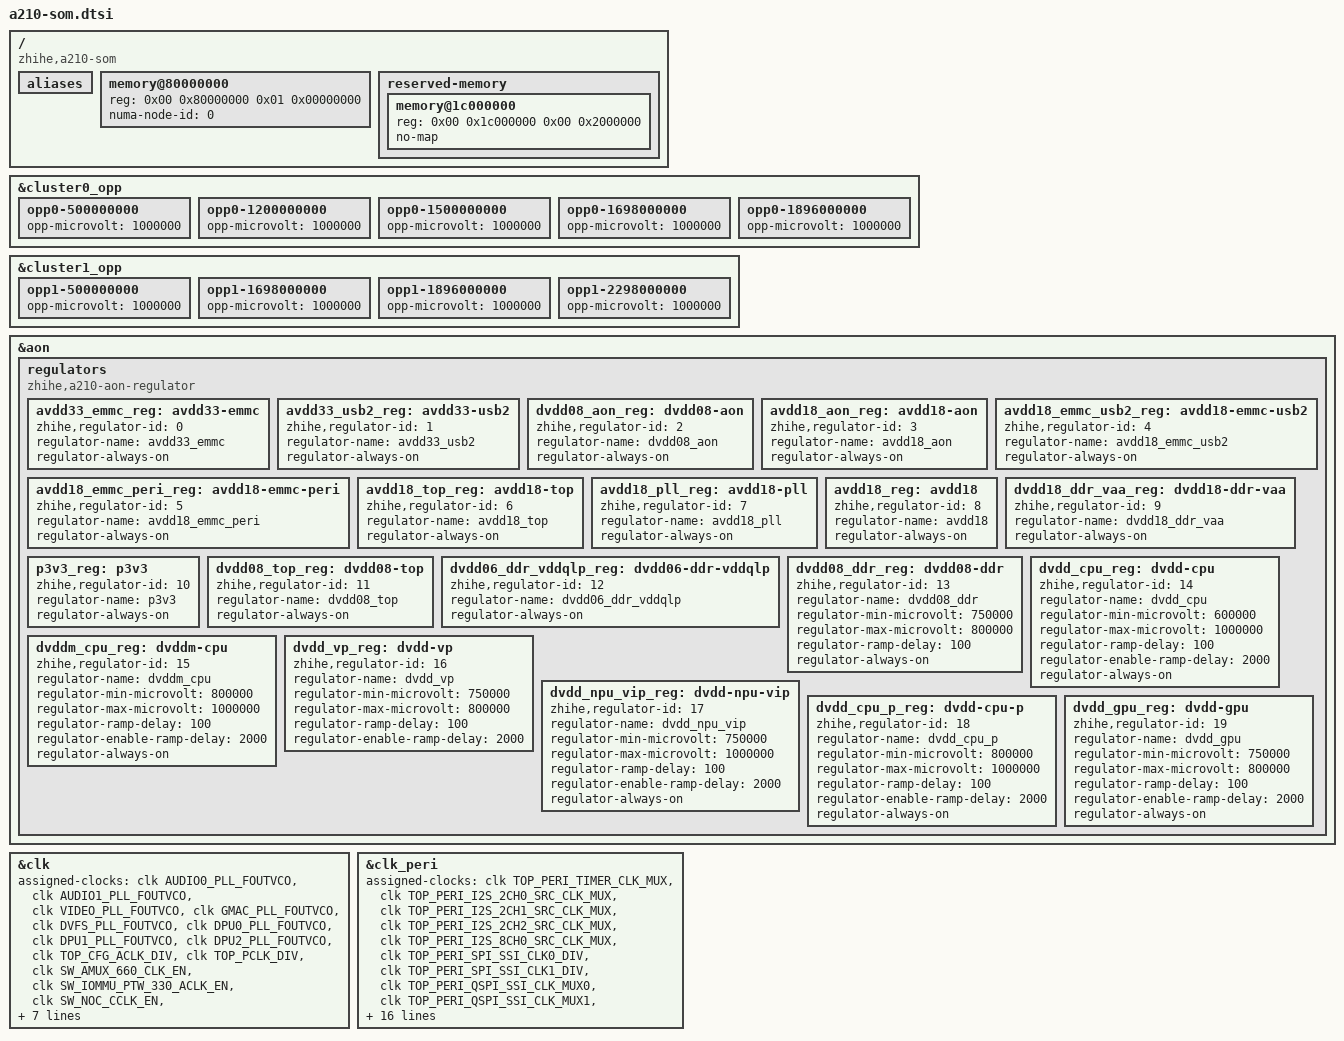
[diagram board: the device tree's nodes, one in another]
// SPDX-License-Identifier: (GPL-2.0-only OR BSD-2-Clause)
/* Shared hardware and operating policy of the A210 SODIMM module. */
#include "a210.dtsi"

/ {
	compatible = "zhihe,a210-som", "zhihe,a210";

	aliases {
	};

	/* Boot firmware replaces this placeholder after DDR training. */
	memory@80000000 {
		device_type = "memory";
		reg = <0x00 0x80000000  0x01 0x00000000>; /* 4G */
		numa-node-id = <0>;
	};

	reserved-memory {
		#address-cells = <2>;
		#size-cells = <2>;
		ranges;

		memory@1c000000 {
			reg = <0x00 0x1c000000 0x00 0x2000000>;
			no-map;
		};
	};
};

&cluster0_opp {
	opp0-500000000 {
		opp-microvolt = <1000000>;
	};
	opp0-1200000000 {
		opp-microvolt = <1000000>;
	};
	opp0-1500000000 {
		opp-microvolt = <1000000>;
	};
	opp0-1698000000 {
		opp-microvolt = <1000000>;
	};
	opp0-1896000000 {
		opp-microvolt = <1000000>;
	};
};

&cluster1_opp {
	opp1-500000000 {
		opp-microvolt = <1000000>;
	};
	opp1-1698000000 {
		opp-microvolt = <1000000>;
	};
	opp1-1896000000 {
		opp-microvolt = <1000000>;
	};
	opp1-2298000000 {
		opp-microvolt = <1000000>;
	};
};

&aon {
	regulators {
		compatible = "zhihe,a210-aon-regulator";

		avdd33_emmc_reg: avdd33-emmc {
			zhihe,regulator-id = <0>;
			regulator-name = "avdd33_emmc";
			regulator-always-on;
		};

		avdd33_usb2_reg: avdd33-usb2 {
			zhihe,regulator-id = <1>;
			regulator-name = "avdd33_usb2";
			regulator-always-on;
		};

		dvdd08_aon_reg: dvdd08-aon {
			zhihe,regulator-id = <2>;
			regulator-name = "dvdd08_aon";
			regulator-always-on;
		};

		avdd18_aon_reg: avdd18-aon {
			zhihe,regulator-id = <3>;
			regulator-name = "avdd18_aon";
			regulator-always-on;
		};

		avdd18_emmc_usb2_reg: avdd18-emmc-usb2 {
			zhihe,regulator-id = <4>;
			regulator-name = "avdd18_emmc_usb2";
			regulator-always-on;
		};

		avdd18_emmc_peri_reg: avdd18-emmc-peri {
			zhihe,regulator-id = <5>;
			regulator-name = "avdd18_emmc_peri";
			regulator-always-on;
		};

		avdd18_top_reg: avdd18-top {
			zhihe,regulator-id = <6>;
			regulator-name = "avdd18_top";
			regulator-always-on;
		};

		avdd18_pll_reg: avdd18-pll {
			zhihe,regulator-id = <7>;
			regulator-name = "avdd18_pll";
			regulator-always-on;
		};

		avdd18_reg: avdd18 {
			zhihe,regulator-id = <8>;
			regulator-name = "avdd18";
			regulator-always-on;
		};

		dvdd18_ddr_vaa_reg: dvdd18-ddr-vaa {
			zhihe,regulator-id = <9>;
			regulator-name = "dvdd18_ddr_vaa";
			regulator-always-on;
		};

		p3v3_reg: p3v3 {
			zhihe,regulator-id = <10>;
			regulator-name = "p3v3";
			regulator-always-on;
		};

		dvdd08_top_reg: dvdd08-top {
			zhihe,regulator-id = <11>;
			regulator-name = "dvdd08_top";
			regulator-always-on;
		};

		dvdd06_ddr_vddqlp_reg: dvdd06-ddr-vddqlp {
			zhihe,regulator-id = <12>;
			regulator-name = "dvdd06_ddr_vddqlp";
			regulator-always-on;
		};

		dvdd08_ddr_reg: dvdd08-ddr {
			zhihe,regulator-id = <13>;
			regulator-name = "dvdd08_ddr";
			regulator-min-microvolt = <750000>;
			regulator-max-microvolt = <800000>;
			regulator-ramp-delay = <100>;
			regulator-always-on;
		};

		dvdd_cpu_reg: dvdd-cpu {
			zhihe,regulator-id = <14>;
			regulator-name = "dvdd_cpu";
			regulator-min-microvolt = <600000>;
			regulator-max-microvolt = <1000000>;
			regulator-ramp-delay = <100>;
			regulator-enable-ramp-delay = <2000>;
			regulator-always-on;
		};

		dvddm_cpu_reg: dvddm-cpu {
			zhihe,regulator-id = <15>;
			regulator-name = "dvddm_cpu";
			regulator-min-microvolt = <800000>;
			regulator-max-microvolt = <1000000>;
			regulator-ramp-delay = <100>;
			regulator-enable-ramp-delay = <2000>;
			regulator-always-on;
		};

		dvdd_vp_reg: dvdd-vp {
			zhihe,regulator-id = <16>;
			regulator-name = "dvdd_vp";
			regulator-min-microvolt = <750000>;
			regulator-max-microvolt = <800000>;
			regulator-ramp-delay = <100>;
			regulator-enable-ramp-delay = <2000>;
		};

		dvdd_npu_vip_reg: dvdd-npu-vip {
			zhihe,regulator-id = <17>;
			regulator-name = "dvdd_npu_vip";
			regulator-min-microvolt = <750000>;
			regulator-max-microvolt = <1000000>;
			regulator-ramp-delay = <100>;
			regulator-enable-ramp-delay = <2000>;
			/* AON power-off also drops the shared C920 enable. */
			regulator-always-on;
		};

		dvdd_cpu_p_reg: dvdd-cpu-p {
			zhihe,regulator-id = <18>;
			regulator-name = "dvdd_cpu_p";
			regulator-min-microvolt = <800000>;
			regulator-max-microvolt = <1000000>;
			regulator-ramp-delay = <100>;
			regulator-enable-ramp-delay = <2000>;
			regulator-always-on;
		};

		dvdd_gpu_reg: dvdd-gpu {
			zhihe,regulator-id = <19>;
			regulator-name = "dvdd_gpu";
			regulator-min-microvolt = <750000>;
			regulator-max-microvolt = <800000>;
			regulator-ramp-delay = <100>;
			regulator-enable-ramp-delay = <2000>;
			/* AON power-off also drops the shared C920 enable. */
			regulator-always-on;
		};
	};
};

&clk {
	assigned-clocks = <&clk AUDIO0_PLL_FOUTVCO>, <&clk AUDIO1_PLL_FOUTVCO>,
			  <&clk VIDEO_PLL_FOUTVCO>, <&clk GMAC_PLL_FOUTVCO>,
			  <&clk DVFS_PLL_FOUTVCO>, <&clk DPU0_PLL_FOUTVCO>,
			  <&clk DPU1_PLL_FOUTVCO>, <&clk DPU2_PLL_FOUTVCO>,
			  <&clk TOP_CFG_ACLK_DIV>, <&clk TOP_PCLK_DIV>,
			  <&clk SW_AMUX_660_CLK_EN>,
			  <&clk SW_IOMMU_PTW_330_ACLK_EN>,
			  <&clk SW_NOC_CCLK_EN>, <&clk TOP_CPUSYS_BUS_CLK_DIV>,
			  <&clk TOP_CPUSYS_PIC_CLK_DIV>;
	assigned-clock-rates = <2359296000>, <2528870400>,
			       <2640000000>, <3000000000>,
			       <1920000000>, <2376000000>,
			       <2376000000>, <2376000000>,
			       <330000000>, <165000000>,
			       <660000000>, <330000000>,
			       <950000000>, <1320000000>,
			       <1000000000>;
};

&clk_peri {
	assigned-clocks = <&clk TOP_PERI_TIMER_CLK_MUX>,
			  <&clk TOP_PERI_I2S_2CH0_SRC_CLK_MUX>,
			  <&clk TOP_PERI_I2S_2CH1_SRC_CLK_MUX>,
			  <&clk TOP_PERI_I2S_2CH2_SRC_CLK_MUX>,
			  <&clk TOP_PERI_I2S_8CH0_SRC_CLK_MUX>,
			  <&clk TOP_PERI_SPI_SSI_CLK0_DIV>,
			  <&clk TOP_PERI_SPI_SSI_CLK1_DIV>,
			  <&clk TOP_PERI_QSPI_SSI_CLK_MUX0>,
			  <&clk TOP_PERI_QSPI_SSI_CLK_MUX1>,
			  <&clk TOP_PERI_PDM_MCLK_DIV>,
			  <&clk TOP_PERI_TDM_SRC_CLK_MUX>,
			  <&clk TOP_PAD_SENSOR_VCLK0_DIV>,
			  <&clk TOP_PAD_SENSOR_VCLK1_DIV>,
			  <&clk TOP_PERI_HIRES_CLK0_DIV>,
			  <&clk TOP_PERI_HIRES_CLK1_DIV>,
			  <&clk TOP_PERI_EMMC_REF_CLK_DIV>,
			  <&clk TOP_PERI_MST_ACLK0_DIV>,
			  <&clk TOP_PERI_MST_CLK1_DIV>,
			  <&clk TOP_TEE_CLK_DIV>;
	assigned-clock-rates = <24000000>, <316108800>,
			       <316108800>, <316108800>,
			       <316108800>, <421478400>,
			       <421478400>, <421478400>,
			       <421478400>, <8426058>,
			       <316108800>, <74250000>,
			       <148500000>, <80000000>,
			       <80000000>, <786432000>,
			       <330000000>, <440000000>,
			       <377142858>;
};
